# cslr_ddr2 register map
Vendor: Texas Instruments
Peripheral module from a debugger description file (folder c6472).
Registers are 32-bit, access not given, reset 0x31030F unless marked. A register's access mark holds for its fields unless they carry their own. Offsets are as the file gives them; lines under a group give offsets from that group; [hi:lo] are bit positions; {n}, {i} and the like mark numbered series; 'fields as' and 'values as' point back to an identical list; <NAME> marks a mode.

## DDR2 — This module provides an interface between the DSP and JESD79D-2A standard compliant DDR2 SDRAM devices.
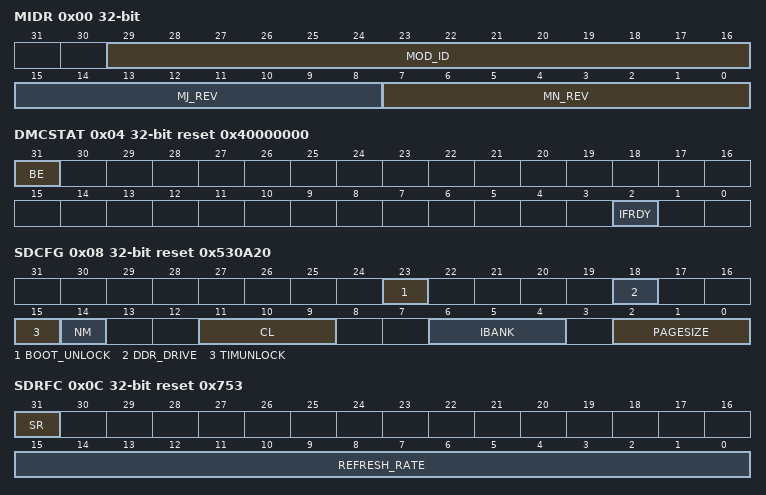
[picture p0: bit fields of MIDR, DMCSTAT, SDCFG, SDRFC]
0x00 MIDR — This register reflects the latest changes made to the memory controller.
  [29:16] MOD_ID ro — Module ID bits.
  [15:8] MJ_REV ro — Major Revision
  [7:0] MN_REV ro — Minor Revision
0x04 DMCSTAT reset 0x40000000 — This register reflects the status of the DDR2 Memory Controller.
  [31] BE ro — Big endian bit. Reflects whether the DDR2 Memory Controller is configured for big or little endian mode.
    1=B_ENDIAN (DDR2 Memory Controller is configured for big endian mode.); 0=L_ENDIAN (DDR2 Memory Controller is configured for little endian mode.)
  [2] IFRDY ro — DDR2 memory controller interface logic ready bit. The interface logic controls the signals used to communicate with DDR2 SDRAM devices. This bit displays the status of the interface logic.
    0=NOTREADY (Interface logic is not ready; either powered down, in reset, or not locked.); 1=READY (Interface logic is powered up, locked, and ready for operation.)
0x08 SDCFG reset 0x530A20 — This register is used to configure the DDR2 Memory Controller access parameters.
  [23] BOOT_UNLOCK rw — Boot unlock bit. Controls write access to bits 16 through 22 of this register.
    0=LOCKED (Writes to bits 22:16 of this register are not permitted.); 1=UNLOCKED (Writes to bits 22:16 of this register are allowed.)
  [18] DDR_DRIVE rw — DDR2 SDRAM drive strength. This bit is used to select the drive strength used by the DDR2 SDRAM. This bit is writeable only when BOOT_UNLOCK is unlocked (set to 1).
    0=NORMAL (Normal drive strength.); 1=WEAK (Weak (60%) drive strength.)
  [15] TIMUNLOCK rw — Timing unlock bit. Controls write access for the SDRAM Timing Register (SDTIM1) and SDRAM Timing Register 2 (SDTIM2). A write to this bit will cause the DDR2 Memory Controller to start the SDRAM initialization sequence.
    0=CLEAR (Register fields in the SDTIM1 and SDTIM2 registers may not be changed.); 1=SET (Register fields in the SDTIM1 and SDTIM2 registers may be changed.)
  [14] NM rw — DDR2 SDRAM data bus width bit. A write to this bit will cause the DDR2 Memory Controller to start the SDRAM initialization sequence.
    0=32BIT (32-bit bus width.); 1=16BIT (16-bit bus width.)
  [11:9] CL rw — CAS latency bits. The value of this field defines the CAS latency, to be used when accessing connected SDRAM devices. A write to this field will cause the DDR2 Memory Controller to start the SDRAM initialization sequence. This field is writeable only when the TIMING_UNLCK bit is unlocked. Values 0, 1, 6, and 7 are reserved for this field.
    2=TWO (CAS Latency of 2); 3=THREE (CAS Latency of 3); 4=FOUR (CAS Latency of 4); 5=FIVE (CAS Latency of 5)
  [6:4] IBANK rw — Internal SDRAM bank setup bits. Defines number of banks inside connected SDRAM devices. A write to this bit will cause the DDR2 Memory Controller to start the SDRAM initialization sequence. Values 4-7 are reserved for this field.
    0=ONE (One bank SDRAM devices); 1=TWO (Two banks SDRAM devices); 2=FOUR (Four banks SDRAM devices); 3=EIGHT (Eight banks SDRAM devices)
  [2:0] PAGESIZE rw — Page size bits. Defines the internal page size of the external DDR2 memory. A write to this bit will cause the DDR2 Memory Controller to start the SDRAM initialization sequence. Values 0, 1, 6, and 7 are reserved for this field. Values 4-7 are reserved for this field.
    0=256W_PAGE (256-word page requiring 8 column address bits.); 1=512W_PAGE (512-word page requiring 9 column address bits.); 2=1024W_PAGE (1024-word page requiring 10 column address bits.); 3=2048W_PAGE (2048-word page requiring 11 column address bits.)
0x0C SDRFC reset 0x753 — This register controls the SDRAM refreshing timing.
  [31] SR rw — Self-refresh bit. Writing a 1 to this bit will cause connected SDRAM devices to be place into Self Refresh mode and the DDR2 Memory Controller to enter the Self Refresh state.
    0=EXIT (Exit self-refresh mode.); 1=ENTER (Enter self-refresh mode.)
  [15:0] REFRESH_RATE rw — Refresh rate bits. The value in this field is used to define the rate at which connected SDRAM devices will be refreshed as follows: SDRAM refresh rate = DDR2CLKOUT clock rate / REFRESH_RATE Writing a value less than 0x0100 to this field will cause it to be loaded with 2 * T_RFC value from the SDRAM Timing 1 Register.
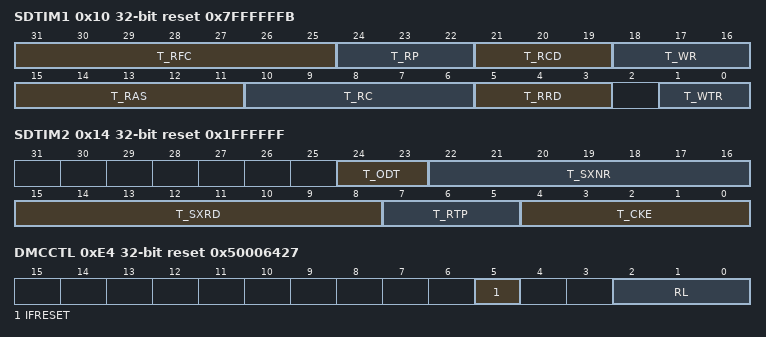
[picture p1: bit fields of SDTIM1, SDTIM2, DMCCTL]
0x10 SDTIM1 reset 0x7FFFFFFB — Configures the timing parameters for SDRAM accesses.
  [31:25] T_RFC rw — These bits specify the minimum number of DDR2CLKOUT cycles from a refresh or load mode command to a refresh or activate command, minus one. The value for these bits can be derived from the trfc AC timing parameter in the DDR2 memory data sheet. Calculate using this formula: T_RFC = (trfc/DDR2CLKOUT) - 1
  [24:22] T_RP rw — These bits specify the minimum number of DDR2CLKOUT cycles from a precharge command to a refresh or activate command, minus 1. The value for these bits can be derived from the trp AC timing parameter in the DDR2 memory data sheet. Calculate using the formula: T_RP = (trp/DDR_CLKO) - 1.
  [21:19] T_RCD rw — These bits specify the minimum number of DDR2CLKOUT cycles from an activate command to a read or write command, minus 1. The value for these bits can be derived from the trcd AC timing parameter in the DDR2 memory data sheet. Calculate using the formula: T_RCD = (trcd/DDR2CLKOUT) - 1
  [18:16] T_WR rw — These bits specify the minimum number of DDR2CLKOUT cycles from the last write transfer to a precharge command, minus 1. The value for these bits can be derived from the twr AC timing parameter in the DDR2 memory data sheet. Calculate using the formula: T_WR = (twr/DDR2CLKOUT) - 1 The SDRAM initialization sequence will be started when the value of this field is changed from the previous value and the DDR2_ENABLE in SDCFG is equal to 1.
  [15:11] T_RAS rw — These bits specify the minimum number of DDR2CLKOUT cycles from an activate command to a precharge command, minus 1. The value for these bits can be derived from the tras AC timing parameter in the DDR2 memory data sheet. Calculate using this formula: T_RAS = (tras/DDR2CLKOUT) - 1 T_RAS must be greater than or equal to T_RCD.
  [10:6] T_RC rw — These bits specify the minimum number of DDR2CLKOUT cycles from an activate command to an activate command, minus 1. The value for these bits can be derived from the trc AC timing parameter in the DDR2 memory data sheet. Calculate using this formula: T_RC = (trc/DDR2CLKOUT) - 1
  [5:3] T_RRD rw — These bits specify the minimum number of DDR2CLKOUT cycles from an activate command to an activate command in a different bank, minus 1. The value for these bits can be derived from the trrd AC timing parameter in the DDR2 memory data sheet. Calculate using this formula: T_RRD = (trrd/DDR2CLKOUT) - 1 When connecting to an 8-bank DDR2 SDRAM, this field must be equal to: T_RRD = ( (4*trdd + 2*tck) / (4*tck) ) - 1
  [1:0] T_WTR rw — These bits specify the minimum number of DDR2CLKOUT cycles from the last write to a read command, minus 1. The value for these bits can be derived from the twtr AC timing parameter in the DDR2 memory data sheet. Calculate using this formula: T_WTR = (twtr/DDR2CLKOUT) - 1
0x14 SDTIM2 reset 0x1FFFFFF — Configures the timing parameters for SDRAM accesses.
  [24:23] T_ODT rw — These bits specify the number of DDR2CLKOUT cycles from ODT enable to write data driven for DDR2 SDRAM. T_ODT must be less than the CAS latency minus one. Calculate using this formula: T_ODT = CAS latency - taond - 1
  [22:16] T_SXNR rw — These bits specify the minimum number of DDR2CLKOUT cycles from a self-refresh exit to any other command except a read command, minus 1. The value for these bits can be derived from the txsnr AC timing parameter in the DDR2 data sheet. Calculate using this formula: T_XSNR = (trtp/DDR2CLKOUT) - 1
  [15:8] T_SXRD rw — These bits specify the minimum number of DDR2CLKOUT cycles from a self-refresh exit to a read command, minus 1. The value for these bits can be derived from the txsrd AC timing parameter in the DDR2 data sheet. Calculate using this formula: T_XSRD = txsrd - 1
  [7:5] T_RTP rw — These bits specify the minimum number of DDR2CLKOUT cycles from a last read command to a precharge command, minus 1. The value for these bits can be derived from the trtp AC timing parameter in the DDR2 data sheet. Calculate using this formula: T_RTP = (trtp/DDR2CLKOUT) - 1
  [4:0] T_CKE rw — These bits specify the minimum number of DDR2CLKOUT cycles between transitions on the DSDCKE pin, minus 1. The value for these bits can be derived from the tcke AC timing parameter in the DDR2 data sheet. Calculate using this formula: T_CKE = tcke - 1
0x20 BPRIO reset 0xFF — Used to temporarily raise the priority of old commands.
  [7:0] PRIO_RAISE rw — Priority raise old counter bits. These bits specify the number of memory transfers after which the DDR2 port will elevate the priority of the oldest command in the command FIFO.
0xE4 DMCCTL reset 0x50006427 — Configures the DDR2 Memory Controller.
  [5] IFRESET rw — DDR2 memory controller interface logic reset. The interface logic controls the signals used to communicate with DDR2 SDRAM devices. This bit resets the interface logic. The status of this interface logic is shown on the DDR2 memory controller status register.
    0=RELEASE (Release reset.); 1=ASSERT (Assert reset.)
  [2:0] RL rw — Read latency bits. These bits must be set equal to the CAS latency plus 1.
